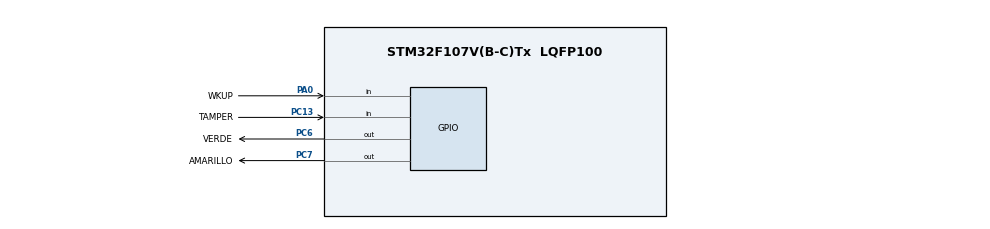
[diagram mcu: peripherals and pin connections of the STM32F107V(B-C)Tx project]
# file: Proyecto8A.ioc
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FREERTOS.Tasks01=defaultTask,24,128,StartDefaultTask,Default,NULL,Dynamic,NULL,NULL;ledVerde,24,128,Start_led_verde,Default,NULL,Dynamic,NULL,NULL;ledAmarillo,24,128,Start_led_amarillo,Default,NULL,Dynamic,NULL,NULL
Mcu.Family=STM32F1
Mcu.Name=STM32F107V(B-C)Tx
Mcu.Package=LQFP100
NVIC.PriorityGroup=NVIC_PRIORITYGROUP_4
NVIC.TIM1_UP_IRQn=true\:15\:0\:false\:false\:true\:false\:false\:true\:true
NVIC.TimeBase=TIM1_UP_IRQn
NVIC.TimeBaseIP=TIM1
PA0-WKUP.GPIO_Label=WKUP
PA0-WKUP.Signal=GPIO_Input
PC13-TAMPER-RTC.GPIO_Label=TAMPER
PC13-TAMPER-RTC.Signal=GPIO_Input
PC6.GPIO_Label=VERDE
PC6.Signal=GPIO_Output
PC7.GPIO_Label=AMARILLO
PC7.Signal=GPIO_Output
ProjectManager.HeapSize=0x200
ProjectManager.StackSize=0x400
ProjectManager.TargetToolchain=STM32CubeIDE
RCC.USBFreq_Value=10666666.666666666
VP_FREERTOS_VS_CMSIS_V2.Mode=CMSIS_V2
VP_SYS_VS_ND.Mode=No_Debug
VP_SYS_VS_tim1.Mode=TIM1
board=custom

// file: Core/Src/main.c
/* USER CODE BEGIN Header */
/**
 ******************************************************************************
 * @file           : main.c
 * @brief          : Main program body
 ******************************************************************************
 * @attention
 *
 * Copyright (c) 2024 STMicroelectronics.
 * All rights reserved.
 *
 * This software is licensed under terms that can be found in the LICENSE file
 * in the root directory of this software component.
 * If no LICENSE file comes with this software, it is provided AS-IS.
 *
 ******************************************************************************
 */
/* USER CODE END Header */
#include "main.h"
#include "cmsis_os.h"

/* Definitions for defaultTask */
osThreadId_t defaultTaskHandle;
const osThreadAttr_t defaultTask_attributes = { .name = "defaultTask",
		.stack_size = 128 * 4, .priority = (osPriority_t) osPriorityNormal, };
/* Definitions for ledVerde */
osThreadId_t ledVerdeHandle;
const osThreadAttr_t ledVerde_attributes = { .name = "ledVerde", .stack_size =
		128 * 4, .priority = (osPriority_t) osPriorityNormal, };
/* Definitions for ledAmarillo */
osThreadId_t ledAmarilloHandle;
const osThreadAttr_t ledAmarillo_attributes = { .name = "ledAmarillo",
		.stack_size = 128 * 4, .priority = (osPriority_t) osPriorityNormal, };

void SystemClock_Config(void);
static void MX_GPIO_Init(void);
void StartDefaultTask(void *argument);
void Start_led_verde(void *argument);
void Start_led_amarillo(void *argument);

int main(void) {

	/* MCU Configuration--------------------------------------------------------*/

	/* Reset of all peripherals, Initializes the Flash interface and the Systick. */
	HAL_Init();

	/* Configure the system clock */
	SystemClock_Config();

	/* Initialize all configured peripherals */
	MX_GPIO_Init();

	/* Init scheduler */
	osKernelInitialize();

	/* Create the thread(s) */
	/* creation of defaultTask */
	defaultTaskHandle = osThreadNew(StartDefaultTask, NULL,
			&defaultTask_attributes);

	/* creation of ledVerde */
	ledVerdeHandle = osThreadNew(Start_led_verde, NULL, &ledVerde_attributes);

	/* creation of ledAmarillo */
	ledAmarilloHandle = osThreadNew(Start_led_amarillo, NULL,
			&ledAmarillo_attributes);

	/* Start scheduler */
	osKernelStart();

	/* We should never get here as control is now taken by the scheduler */
	/* Infinite loop */
	while (1) {

	}
}

void SystemClock_Config(void) {
	RCC_OscInitTypeDef RCC_OscInitStruct = { 0 };
	RCC_ClkInitTypeDef RCC_ClkInitStruct = { 0 };

	/** Initializes the RCC Oscillators according to the specified parameters
	 * in the RCC_OscInitTypeDef structure.
	 */
	RCC_OscInitStruct.OscillatorType = RCC_OSCILLATORTYPE_HSI;
	RCC_OscInitStruct.HSIState = RCC_HSI_ON;
	RCC_OscInitStruct.HSICalibrationValue = RCC_HSICALIBRATION_DEFAULT;
	RCC_OscInitStruct.PLL.PLLState = RCC_PLL_NONE;
	RCC_OscInitStruct.PLL2.PLL2State = RCC_PLL_NONE;
	if (HAL_RCC_OscConfig(&RCC_OscInitStruct) != HAL_OK) {
		Error_Handler();
	}

	/** Initializes the CPU, AHB and APB buses clocks
	 */
	RCC_ClkInitStruct.ClockType = RCC_CLOCKTYPE_HCLK | RCC_CLOCKTYPE_SYSCLK
			| RCC_CLOCKTYPE_PCLK1 | RCC_CLOCKTYPE_PCLK2;
	RCC_ClkInitStruct.SYSCLKSource = RCC_SYSCLKSOURCE_HSI;
	RCC_ClkInitStruct.AHBCLKDivider = RCC_SYSCLK_DIV1;
	RCC_ClkInitStruct.APB1CLKDivider = RCC_HCLK_DIV1;
	RCC_ClkInitStruct.APB2CLKDivider = RCC_HCLK_DIV1;

	if (HAL_RCC_ClockConfig(&RCC_ClkInitStruct, FLASH_LATENCY_0) != HAL_OK) {
		Error_Handler();
	}

	/** Configure the Systick interrupt time
	 */
	__HAL_RCC_PLLI2S_ENABLE();
}

static void MX_GPIO_Init(void) {
	GPIO_InitTypeDef GPIO_InitStruct = { 0 };

	/* GPIO Ports Clock Enable */
	__HAL_RCC_GPIOC_CLK_ENABLE();
	__HAL_RCC_GPIOA_CLK_ENABLE();

	/*Configure GPIO pin Output Level */
	HAL_GPIO_WritePin(GPIOC, VERDE_Pin | AMARILLO_Pin, GPIO_PIN_RESET);

	/*Configure GPIO pin : TAMPER_Pin */
	GPIO_InitStruct.Pin = TAMPER_Pin;
	GPIO_InitStruct.Mode = GPIO_MODE_INPUT;
	GPIO_InitStruct.Pull = GPIO_NOPULL;
	HAL_GPIO_Init(TAMPER_GPIO_Port, &GPIO_InitStruct);

	/*Configure GPIO pin : WKUP_Pin */
	GPIO_InitStruct.Pin = WKUP_Pin;
	GPIO_InitStruct.Mode = GPIO_MODE_INPUT;
	GPIO_InitStruct.Pull = GPIO_NOPULL;
	HAL_GPIO_Init(WKUP_GPIO_Port, &GPIO_InitStruct);

	/*Configure GPIO pins : VERDE_Pin AMARILLO_Pin */
	GPIO_InitStruct.Pin = VERDE_Pin | AMARILLO_Pin;
	GPIO_InitStruct.Mode = GPIO_MODE_OUTPUT_PP;
	GPIO_InitStruct.Pull = GPIO_NOPULL;
	GPIO_InitStruct.Speed = GPIO_SPEED_FREQ_LOW;
	HAL_GPIO_Init(GPIOC, &GPIO_InitStruct);

}

void StartDefaultTask(void *argument) {
	for (;;) {
		osDelay(1);
	}
}

void Start_led_verde(void *argument) {
	/* USER CODE BEGIN Start_led_verde */
	/* Infinite loop */
	for (;;) {
		HAL_GPIO_WritePin(VERDE_GPIO_Port, VERDE_Pin, GPIO_PIN_SET);
		osDelay(300);
		HAL_GPIO_WritePin(VERDE_GPIO_Port, VERDE_Pin, GPIO_PIN_RESET);
		osDelay(300);
	}
	/* USER CODE END Start_led_verde */
}

void Start_led_amarillo(void *argument) {
	/* USER CODE BEGIN Start_led_amarillo */
	/* Infinite loop */
	for (;;) {
		HAL_GPIO_WritePin(AMARILLO_GPIO_Port, AMARILLO_Pin,GPIO_PIN_SET);
		osDelay(200);
		HAL_GPIO_WritePin(AMARILLO_GPIO_Port, AMARILLO_Pin,GPIO_PIN_RESET);
		osDelay(200);
	}
	/* USER CODE END Start_led_amarillo */
}

void HAL_TIM_PeriodElapsedCallback(TIM_HandleTypeDef *htim) {
	if (htim->Instance == TIM1) {
		HAL_IncTick();
	}
}

void Error_Handler(void) {
	__disable_irq();
	while (1) {
	}
}
